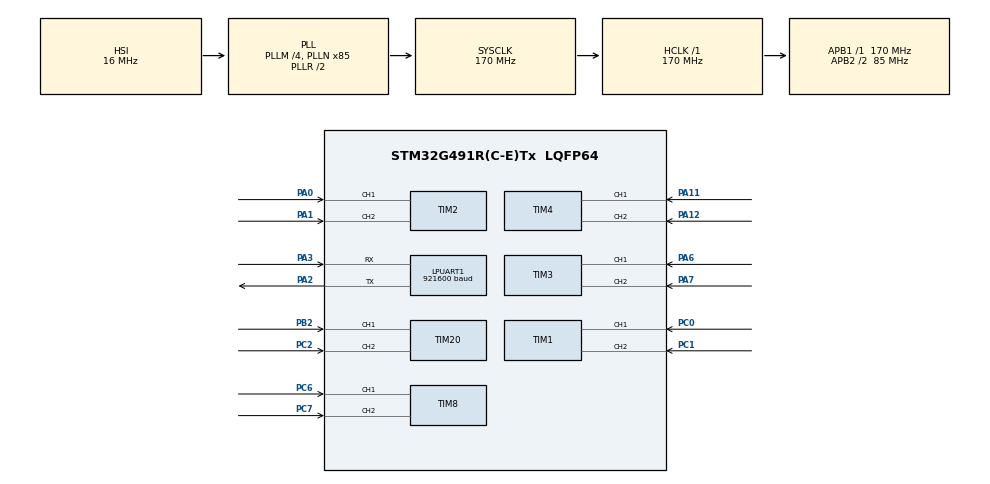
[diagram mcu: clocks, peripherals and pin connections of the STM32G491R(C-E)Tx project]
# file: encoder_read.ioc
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Dma.LPUART1_TX.0.Direction=DMA_MEMORY_TO_PERIPH
Dma.LPUART1_TX.0.EventEnable=DISABLE
Dma.LPUART1_TX.0.Instance=DMA1_Channel1
Dma.LPUART1_TX.0.MemDataAlignment=DMA_MDATAALIGN_BYTE
Dma.LPUART1_TX.0.MemInc=DMA_MINC_ENABLE
Dma.LPUART1_TX.0.Mode=DMA_NORMAL
Dma.LPUART1_TX.0.PeriphDataAlignment=DMA_PDATAALIGN_BYTE
Dma.LPUART1_TX.0.PeriphInc=DMA_PINC_DISABLE
Dma.LPUART1_TX.0.Polarity=HAL_DMAMUX_REQ_GEN_RISING
Dma.LPUART1_TX.0.Priority=DMA_PRIORITY_LOW
Dma.LPUART1_TX.0.RequestNumber=1
Dma.LPUART1_TX.0.SignalID=NONE
Dma.LPUART1_TX.0.SyncEnable=DISABLE
Dma.LPUART1_TX.0.SyncPolarity=HAL_DMAMUX_SYNC_NO_EVENT
Dma.LPUART1_TX.0.SyncRequestNumber=1
Dma.LPUART1_TX.0.SyncSignalID=NONE
Dma.Request0=LPUART1_TX
LPUART1.BaudRate=921600
Mcu.Family=STM32G4
Mcu.Name=STM32G491R(C-E)Tx
Mcu.Package=LQFP64
NVIC.DMA1_Channel1_IRQn=true\:0\:0\:false\:false\:true\:false\:true\:true
NVIC.LPUART1_IRQn=true\:0\:0\:false\:false\:true\:true\:true\:true
NVIC.PriorityGroup=NVIC_PRIORITYGROUP_4
PA0.GPIO_PuPd=GPIO_PULLUP
PA0.Signal=S_TIM2_CH1
PA1.GPIO_PuPd=GPIO_PULLUP
PA1.Signal=S_TIM2_CH2
PA11.GPIO_PuPd=GPIO_PULLUP
PA11.Signal=S_TIM4_CH1
PA12.GPIO_PuPd=GPIO_PULLUP
PA12.Signal=S_TIM4_CH2
PA2.Mode=Asynchronous
PA2.Signal=LPUART1_TX
PA3.Mode=Asynchronous
PA3.Signal=LPUART1_RX
PA6.GPIO_PuPd=GPIO_PULLUP
PA6.Signal=S_TIM3_CH1
PA7.GPIO_PuPd=GPIO_PULLUP
PA7.Signal=S_TIM3_CH2
PB2.GPIO_PuPd=GPIO_PULLUP
PB2.Signal=S_TIM20_CH1
PC0.GPIO_PuPd=GPIO_PULLUP
PC0.Signal=S_TIM1_CH1
PC1.GPIO_PuPd=GPIO_PULLUP
PC1.Signal=S_TIM1_CH2
PC2.GPIO_PuPd=GPIO_PULLUP
PC2.Signal=S_TIM20_CH2
PC6.GPIO_PuPd=GPIO_PULLUP
PC6.Signal=S_TIM8_CH1
PC7.GPIO_PuPd=GPIO_PULLUP
PC7.Signal=S_TIM8_CH2
ProjectManager.HeapSize=0x200
ProjectManager.StackSize=0x400
ProjectManager.TargetToolchain=STM32CubeIDE
RCC.ADC12Freq_Value=170000000
RCC.ADC345Freq_Value=170000000
RCC.AHBFreq_Value=170000000
RCC.APB1Freq_Value=170000000
RCC.APB1TimFreq_Value=170000000
RCC.APB2CLKDivider=RCC_HCLK_DIV2
RCC.APB2Freq_Value=85000000
RCC.APB2TimFreq_Value=170000000
RCC.CortexFreq_Value=170000000
RCC.EXTERNAL_CLOCK_VALUE=12288000
RCC.HCLKFreq_Value=170000000
RCC.HSE_VALUE=24000000
RCC.HSI48_VALUE=48000000
RCC.HSI_VALUE=16000000
RCC.LSE_VALUE=32768
RCC.PLLM=RCC_PLLM_DIV4
RCC.PLLN=85
RCC.SYSCLKFreq_VALUE=170000000
RCC.SYSCLKSource=RCC_SYSCLKSOURCE_PLLCLK
RCC.VCOOutputFreq_Value=340000000
SH.S_TIM1_CH1.0=TIM1_CH1,Encoder_Interface
SH.S_TIM1_CH2.0=TIM1_CH2,Encoder_Interface
SH.S_TIM20_CH1.0=TIM20_CH1,Encoder_Interface
SH.S_TIM20_CH2.0=TIM20_CH2,Encoder_Interface
SH.S_TIM2_CH1.0=TIM2_CH1,Encoder_Interface
SH.S_TIM2_CH2.0=TIM2_CH2,Encoder_Interface
SH.S_TIM3_CH1.0=TIM3_CH1,Encoder_Interface
SH.S_TIM3_CH2.0=TIM3_CH2,Encoder_Interface
SH.S_TIM4_CH1.0=TIM4_CH1,Encoder_Interface
SH.S_TIM4_CH2.0=TIM4_CH2,Encoder_Interface
SH.S_TIM8_CH1.0=TIM8_CH1,Encoder_Interface
SH.S_TIM8_CH2.0=TIM8_CH2,Encoder_Interface
TIM1.EncoderMode=TIM_ENCODERMODE_TI12
TIM1.IC1Filter=15
TIM1.IC2Filter=15
TIM2.EncoderMode=TIM_ENCODERMODE_TI12
TIM2.IC1Filter=15
TIM2.IC2Filter=15
TIM20.EncoderMode=TIM_ENCODERMODE_TI12
TIM20.IC1Filter=15
TIM20.IC2Filter=15
TIM3.EncoderMode=TIM_ENCODERMODE_TI12
TIM3.IC1Filter=15
TIM3.IC2Filter=15
TIM4.EncoderMode=TIM_ENCODERMODE_TI12
TIM4.IC1Filter=15
TIM4.IC2Filter=15
TIM8.EncoderMode=TIM_ENCODERMODE_TI12
TIM8.IC1Filter=15
TIM8.IC2Filter=15
VP_SYS_VS_DBSignals.Mode=DisableDeadBatterySignals
board=custom

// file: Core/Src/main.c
/* USER CODE BEGIN Header */
/**
  ******************************************************************************
  * @file           : main.c
  * @brief          : Main program body
  ******************************************************************************
  * @attention
  *
  * Copyright (c) 2026 STMicroelectronics.
  * All rights reserved.
  *
  * This software is licensed under terms that can be found in the LICENSE file
  * in the root directory of this software component.
  * If no LICENSE file comes with this software, it is provided AS-IS.
  *
  ******************************************************************************
  */
/* USER CODE END Header */
#include "main.h"
#include "dma.h"
#include "usart.h"
#include "tim.h"
#include "gpio.h"

/* USER CODE BEGIN Includes */
#include "encoder_stream.h"

/* USER CODE END Includes */

void SystemClock_Config(void);

int main(void)
{

  /* MCU Configuration--------------------------------------------------------*/

  /* Reset of all peripherals, Initializes the Flash interface and the Systick. */
  HAL_Init();

  /* Configure the system clock */
  SystemClock_Config();

  /* Initialize all configured peripherals */
  MX_GPIO_Init();
  MX_DMA_Init();
  MX_LPUART1_UART_Init();
  MX_TIM1_Init();
  MX_TIM2_Init();
  MX_TIM3_Init();
  MX_TIM4_Init();
  MX_TIM8_Init();
  MX_TIM20_Init();
  /* USER CODE BEGIN 2 */
  EncStream_Init();

  /* USER CODE END 2 */

  /* Infinite loop */
  while (1)
  {

    /* USER CODE BEGIN 3 */
    EncStream_Task();
  }
  /* USER CODE END 3 */
}

void SystemClock_Config(void)
{
  RCC_OscInitTypeDef RCC_OscInitStruct = {0};
  RCC_ClkInitTypeDef RCC_ClkInitStruct = {0};

  /** Configure the main internal regulator output voltage
  */
  HAL_PWREx_ControlVoltageScaling(PWR_REGULATOR_VOLTAGE_SCALE1_BOOST);

  /** Initializes the RCC Oscillators according to the specified parameters
  * in the RCC_OscInitTypeDef structure.
  */
  RCC_OscInitStruct.OscillatorType = RCC_OSCILLATORTYPE_HSI;
  RCC_OscInitStruct.HSIState = RCC_HSI_ON;
  RCC_OscInitStruct.HSICalibrationValue = RCC_HSICALIBRATION_DEFAULT;
  RCC_OscInitStruct.PLL.PLLState = RCC_PLL_ON;
  RCC_OscInitStruct.PLL.PLLSource = RCC_PLLSOURCE_HSI;
  RCC_OscInitStruct.PLL.PLLM = RCC_PLLM_DIV4;
  RCC_OscInitStruct.PLL.PLLN = 85;
  RCC_OscInitStruct.PLL.PLLP = RCC_PLLP_DIV2;
  RCC_OscInitStruct.PLL.PLLQ = RCC_PLLQ_DIV2;
  RCC_OscInitStruct.PLL.PLLR = RCC_PLLR_DIV2;
  if (HAL_RCC_OscConfig(&RCC_OscInitStruct) != HAL_OK)
  {
    Error_Handler();
  }

  /** Initializes the CPU, AHB and APB buses clocks
  */
  RCC_ClkInitStruct.ClockType = RCC_CLOCKTYPE_HCLK|RCC_CLOCKTYPE_SYSCLK
                              |RCC_CLOCKTYPE_PCLK1|RCC_CLOCKTYPE_PCLK2;
  RCC_ClkInitStruct.SYSCLKSource = RCC_SYSCLKSOURCE_PLLCLK;
  RCC_ClkInitStruct.AHBCLKDivider = RCC_SYSCLK_DIV1;
  RCC_ClkInitStruct.APB1CLKDivider = RCC_HCLK_DIV1;
  RCC_ClkInitStruct.APB2CLKDivider = RCC_HCLK_DIV2;

  if (HAL_RCC_ClockConfig(&RCC_ClkInitStruct, FLASH_LATENCY_4) != HAL_OK)
  {
    Error_Handler();
  }
}

void Error_Handler(void)
{
  __disable_irq();
  while (1)
  {
  }
}
